# pse84 register map
Vendor: Cypress Semiconductor; Series: PSE84; File version: 1.0
CPU: CM33 r0p1, little endian, MPU, FPU, VTOR, 3 interrupt priority bits
Registers are 32-bit, read-write, reset 0x0 unless marked. A register's access mark holds for its fields unless they carry their own. Offsets are from the block's base; [hi:lo] are bit positions.

## CANFD0 (part 3 of 3) — CAN Controller
Base 0x42840000
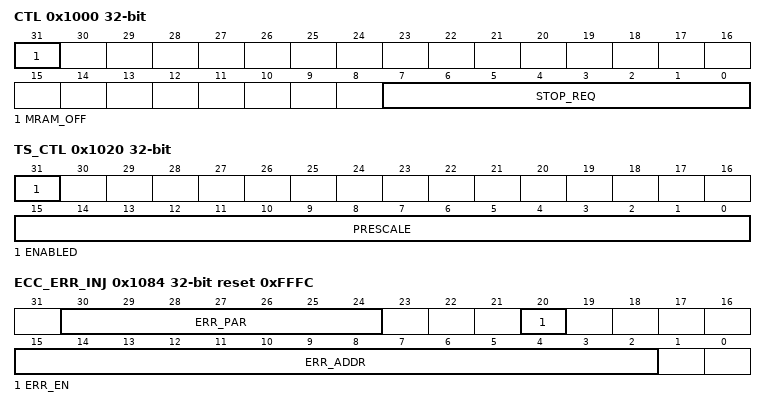
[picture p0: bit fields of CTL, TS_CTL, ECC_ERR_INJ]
0x1000 CTL — Global CAN control register
  [31] MRAM_OFF — MRAM off 0= Default MRAM on (with MRAM retained in DeepSleep). 1= Switch MRAM off (not retained) to save power. Before setting this bit all the CAN channels have to be powered down using the STOP_REQ/ACK bits. When the MRAM is off any access attempt to it is considered an address error (as if MRAM_SIZE=0). After switching the MRAM on again software needs to allow for a certain power up time before MRAM can be used, i.e. before STOP_REQ can be de-asserted. The power up time is equivalent to the system SRAM power up time specified in the CPUSS.RAM_PWR_DELAY_CTL register. To meet S8 platform requirements, MRAM_OFF should be set to 0 prior to transitioning to Hibernate mode.
  [7:0] STOP_REQ — Clock Stop Request for each TTCAN IP . The m_ttcan_clkstop_req of each TTCAN IP is directly driven by these bits.
0x1004 STATUS ro — Global CAN status register
  [7:0] STOP_ACK — Clock Stop Acknowledge for each TTCAN IP. These bits are directly driven by m_ttcan_clkstop_ack of each TTCAN IP. When this bit is set the corresponding TTCAN IP clocks will be gated off, except HCLK will enabled for each AHB write
0x1010 INTR0_CAUSE ro — Consolidated interrupt0 cause register
  [7:0] INT0 — Show pending m_ttcan_int0 of each channel
0x1014 INTR1_CAUSE ro — Consolidated interrupt1 cause register
  [7:0] INT1 — Show pending m_ttcan_int1 of each channel
0x1020 TS_CTL — Time Stamp control register
  [31] ENABLED — Counter enable bit 0 = Count disabled. Stop counting up and keep the counter value 1 = Count enabled. Start counting up from the current value
  [15:0] PRESCALE — Time Stamp counter prescale value. When enabled divide the Host clock (HCLK) by PRESCALE+1 to create Time Stamp clock ticks.
0x1024 TS_CNT — Time Stamp counter value
  [15:0] VALUE — The counter value of the Time Stamp Counter. When enabled this counter will count Time Stamp clock ticks from the pre-scaler. When written this counter and the pre-scaler will reset to 0 (write data is ignored).
0x1080 ECC_CTL — ECC control
  [16] ECC_EN — Enable ECC for CANFD SRAM When disabled also all error injection functionality is disabled.
0x1084 ECC_ERR_INJ reset 0xFFFC — ECC error injection
  [30:24] ERR_PAR — ECC Parity bits to use for ECC error injection at address ERR_ADDR.
  [20] ERR_EN — Enable error injection (ECC_EN must be 1). When this bit is set the error parity (ERR_PAR) will be used when an AHB write is done to the ERR_ADDR address. When the error word is read a single or double error will be reported to the fault structure just like for a real ECC error (even if this bit is no longer set). When this bit is set (and ECC_EN=1) a non-correctable error (ECC or address error) for the ERR_ADDR will not be reported back to the CAN channel or AHB bus.
  [15:2] ERR_ADDR — Specifies the address of the word where an error will be injected on write or an non-correctable error will be suppressed. When the ERR_EN bit is set an error parity (ERR_PAR) is injected when any write, from bus or a CAN channel, is done to this address. When the ERR_EN bit is set and the access address matches ERR_ADDR then a non-correctable ECC error or an Address error will NOT result in a bus error or CAN channel shutdown. Note that error reporting to the fault structure cannot be suppressed.

## PD — Power Domain Controller
Base 0x44103000
0x00 CTL — Power Domain Control
  [0] BLEED_EN — Activates bleed feature for the controlled power domain
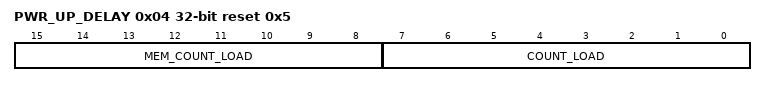
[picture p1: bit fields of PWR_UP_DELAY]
0x04 PWR_UP_DELAY reset 0x5 — Active switch weak enable to active switch strong enable delay
  [15:8] MEM_COUNT_LOAD — Load value for counter running on clk_pwr (10MHz) providing the timing from weak MEM switch enable to strong MEM switch enable. Default is 5 for ~500ns
  [7:0] COUNT_LOAD — Load value for counter running on clk_pwr (10MHz) providing the timing from weak ACTIVE switch enable to strong ACTIVE switch enable. Default is 5 for ~500ns
